VERSION ""

NS_ :

BS_:

BU_: EPS ESP_ECU BCM VCU MPC_CAM ADAS_ECU MCU BSD

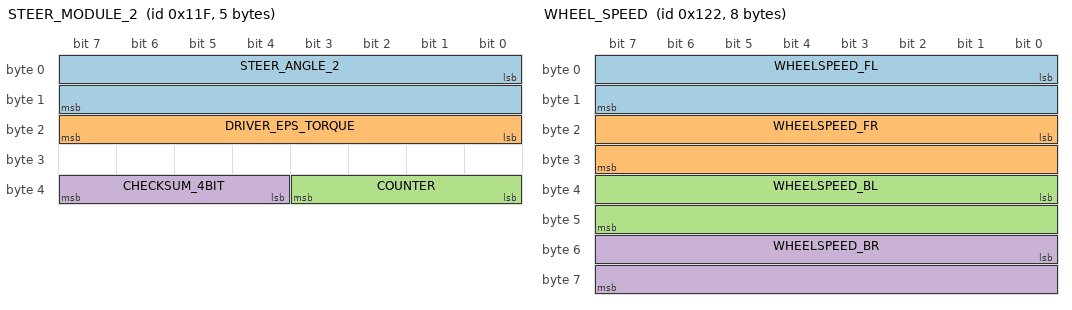
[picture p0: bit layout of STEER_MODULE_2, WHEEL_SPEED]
BO_ 287 STEER_MODULE_2: 5 EPS
 SG_ STEER_ANGLE_2 : 0|16@1- (0.1,0) [-780|780] "deg" MCU,ADAS_ECU
 SG_ DRIVER_EPS_TORQUE : 16|8@1+ (1,0) [0|255] "" MCU,ADAS_ECU
 SG_ COUNTER : 35|4@0+ (1,0) [0|15] "" MCU
 SG_ CHECKSUM_4BIT : 39|4@0+ (1,0) [0|15] "" MCU

BO_ 290 WHEEL_SPEED: 8 ESP_ECU
 SG_ WHEELSPEED_FL : 0|16@1+ (0.1,0) [0|6553.5] "kph" MCU,ADAS_ECU
 SG_ WHEELSPEED_FR : 16|16@1+ (0.1,0) [0|6553.5] "kph" MCU,ADAS_ECU
 SG_ WHEELSPEED_BL : 32|16@1+ (0.1,0) [0|6553.5] "kph" MCU,ADAS_ECU
 SG_ WHEELSPEED_BR : 48|16@1+ (0.1,0) [0|6553.5] "kph" MCU,ADAS_ECU

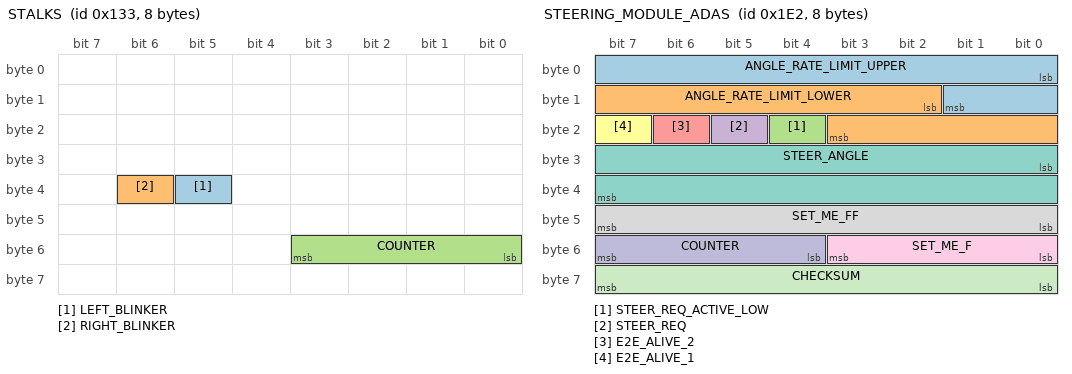
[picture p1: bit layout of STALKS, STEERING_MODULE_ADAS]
BO_ 307 STALKS: 8 BCM
 SG_ LEFT_BLINKER : 37|1@0+ (1,0) [0|1] "" MCU
 SG_ RIGHT_BLINKER : 38|1@0+ (1,0) [0|1] "" MCU
 SG_ COUNTER : 48|4@1+ (1,0) [0|15] "" MCU

BO_ 482 STEERING_MODULE_ADAS: 8 ADAS_ECU
 SG_ ANGLE_RATE_LIMIT_UPPER : 0|10@1- (1,0) [-512|511] "" EPS
 SG_ ANGLE_RATE_LIMIT_LOWER : 10|10@1- (1,0) [-512|511] "" EPS
 SG_ STEER_REQ_ACTIVE_LOW : 20|1@0+ (1,0) [0|1] "" EPS
 SG_ STEER_REQ : 21|1@0+ (1,0) [0|1] "" EPS
 SG_ E2E_ALIVE_2 : 22|1@0+ (1,0) [0|1] "" EPS
 SG_ E2E_ALIVE_1 : 23|1@0+ (1,0) [0|1] "" EPS
 SG_ STEER_ANGLE : 24|16@1- (0.1,0) [-3276.8|3276.7] "deg" EPS
 SG_ SET_ME_FF : 47|8@0+ (1,0) [0|255] "" EPS
 SG_ SET_ME_F : 48|4@1+ (1,0) [0|15] "" EPS
 SG_ COUNTER : 55|4@0+ (1,0) [0|15] "" EPS
 SG_ CHECKSUM : 56|8@1+ (1,0) [0|255] "" EPS

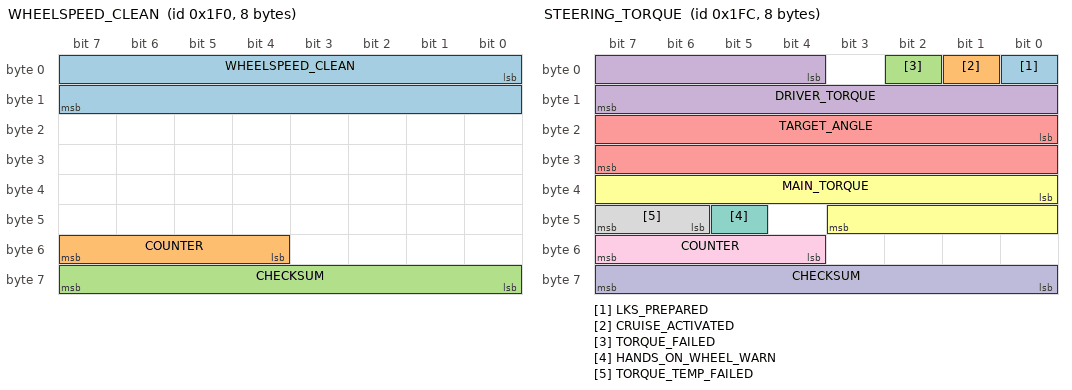
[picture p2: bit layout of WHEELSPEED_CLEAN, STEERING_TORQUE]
BO_ 496 WHEELSPEED_CLEAN: 8 ESP_ECU
 SG_ WHEELSPEED_CLEAN : 0|16@1+ (0.0713,0) [0|4672.6] "kph" MCU
 SG_ COUNTER : 55|4@0+ (1,0) [0|15] "" MCU
 SG_ CHECKSUM : 56|8@1+ (1,0) [0|255] "" MCU

BO_ 508 STEERING_TORQUE: 8 EPS
 SG_ LKS_PREPARED : 0|1@1+ (1,0) [0|1] "" MCU,ADAS_ECU
 SG_ CRUISE_ACTIVATED : 1|1@1+ (1,0) [0|1] "" MCU,ADAS_ECU
 SG_ TORQUE_FAILED : 2|1@1+ (1,0) [0|1] "" MCU,ADAS_ECU
 SG_ DRIVER_TORQUE : 4|12@1- (0.1,0) [-204.8|204.7] "Nm" MCU,ADAS_ECU
 SG_ TARGET_ANGLE : 16|16@1- (0.1,0) [-3276.8|3276.7] "deg" MCU,ADAS_ECU
 SG_ MAIN_TORQUE : 32|12@1- (1,0) [-2048|2047] "" MCU,ADAS_ECU
 SG_ HANDS_ON_WHEEL_WARN : 45|1@1+ (1,0) [0|1] "" MCU,ADAS_ECU
 SG_ TORQUE_TEMP_FAILED : 46|2@1+ (1,0) [0|3] "" MCU,ADAS_ECU
 SG_ COUNTER : 52|4@1+ (1,0) [0|15] "" MCU
 SG_ CHECKSUM : 56|8@1+ (1,0) [0|255] "" MCU

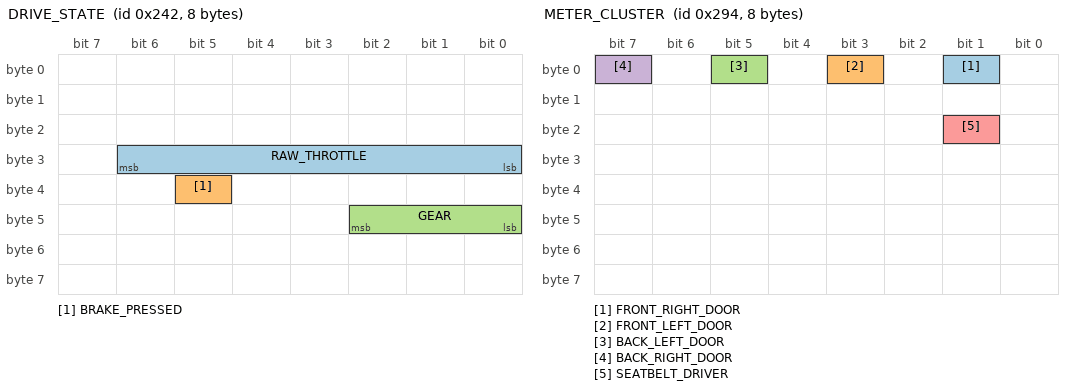
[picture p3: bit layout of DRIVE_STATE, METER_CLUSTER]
BO_ 578 DRIVE_STATE: 8 VCU
 SG_ RAW_THROTTLE : 30|7@0+ (1,0) [0|127] "" MCU
 SG_ BRAKE_PRESSED : 37|1@0+ (1,0) [0|1] "" MCU,ADAS_ECU
 SG_ GEAR : 40|3@1+ (1,0) [0|7] "" MCU

BO_ 660 METER_CLUSTER: 8 BCM
 SG_ FRONT_RIGHT_DOOR : 1|1@1+ (1,0) [0|1] "" MCU
 SG_ FRONT_LEFT_DOOR : 3|1@0+ (1,0) [0|1] "" MCU
 SG_ BACK_LEFT_DOOR : 5|1@1+ (1,0) [0|1] "" MCU
 SG_ BACK_RIGHT_DOOR : 7|1@0+ (1,0) [0|1] "" MCU
 SG_ SEATBELT_DRIVER : 17|1@0+ (1,0) [0|1] "" MCU

BO_ 790 LKAS_HUD_ADAS: 8 MPC_CAM
 SG_ AUTO_LIGHT : 1|2@0+ (1,0) [0|3] "" XXX
 SG_ PT1 : 2|2@1+ (1,0) [0|3] "" MCU
 SG_ LEFT_LANE_STATE : 4|2@1+ (1,0) [0|3] "" MCU
 SG_ LKS_MODE : 6|2@1+ (1,0) [0|3] "" MCU
 SG_ PT2 : 8|2@1+ (1,0) [0|3] "" MCU
 SG_ HANDS_ON_WHEEL_REQ : 10|1@1+ (1,0) [0|1] "" MCU
 SG_ TJA_ICA_STATE : 11|4@1+ (1,0) [0|15] "" MCU
 SG_ HMA_ON_OFF : 15|1@0+ (1,0) [0|1] "" MCU
 SG_ LKAS_OUTPUT : 16|11@1- (1,0) [-1024|1023] "" MCU
 SG_ LKAS_REQ_PREPARE : 27|1@1+ (1,0) [0|1] "" MCU
 SG_ LKAS_ACTIVE : 28|1@1+ (1,0) [0|1] "" MCU
 SG_ SLA_STATE : 29|3@1+ (1,0) [0|7] "" MCU
 SG_ PT3 : 32|2@1+ (1,0) [0|3] "" MCU
 SG_ RIGHT_LANE_STATE : 34|2@1+ (1,0) [0|3] "" MCU
 SG_ LKAS_STATE : 36|4@1+ (1,0) [0|15] "" MCU
 SG_ SPEED_LIMIT_VALUE : 40|8@1+ (5,-5) [-5|1270] "kph" MCU
 SG_ LDSW_TYPE : 49|2@0+ (1,0) [0|3] "" MCU
 SG_ PT4 : 50|2@1+ (1,0) [0|3] "" MCU
 SG_ COUNTER : 52|4@1+ (1,0) [0|15] "" MCU
 SG_ CHECKSUM : 56|8@1+ (1,0) [0|255] "" MCU

BO_ 813 ACC_HUD_ADAS: 8 ADAS_ECU
 SG_ SET_SPEED : 0|8@1+ (0.5,0) [0|127.5] "kph" MCU
 SG_ SET_DISTANCE : 12|3@0+ (1,0) [0|7] "" MCU
 SG_ ACC_STATE : 19|3@1+ (1,0) [0|7] "" MCU
 SG_ ACC_ON2 : 20|1@0+ (1,0) [0|1] "" MCU
 SG_ ACC_ON1 : 22|1@0+ (1,0) [0|1] "" MCU
 SG_ SET_ME_XFF : 47|8@0+ (1,0) [0|255] "" MCU
 SG_ COUNTER : 48|4@1+ (1,0) [0|15] "" MCU
 SG_ SET_ME_XF : 55|4@0+ (1,0) [0|15] "" MCU
 SG_ CHECKSUM : 56|8@1+ (1,0) [0|255] "" MCU

BO_ 814 ACC_CMD: 8 ADAS_ECU
 SG_ ACCEL_CMD : 0|8@1+ (0.05,-5) [-5|7.75] "m/s^2" MCU
 SG_ ACC_ON_1 : 9|1@0+ (1,0) [0|1] "" MCU
 SG_ SET_ME_25_1 : 10|6@1+ (1,0) [0|63] "" MCU
 SG_ ACC_ON_2 : 17|1@0+ (1,0) [0|1] "" MCU
 SG_ SET_ME_25_2 : 18|6@1+ (1,0) [0|63] "" MCU
 SG_ DECEL_FACTOR : 24|4@1+ (1,0) [0|15] "" MCU
 SG_ SET_ME_X8 : 31|4@0+ (1,0) [0|15] "" MCU
 SG_ ACCEL_FACTOR : 32|4@1+ (1,0) [0|15] "" MCU
 SG_ CMD_REQ_ACTIVE_LOW : 36|1@0+ (1,0) [0|1] "" MCU
 SG_ SET_ME_1 : 38|1@0+ (1,0) [0|1] "" MCU
 SG_ STANDSTILL_RESUME : 39|1@0+ (1,0) [0|1] "" MCU
 SG_ STANDSTILL_STATE : 40|1@0+ (1,0) [0|1] "" MCU
 SG_ ACC_REQ_NOT_STANDSTILL : 43|1@0+ (1,0) [0|1] "" MCU
 SG_ ACC_CONTROLLABLE_AND_ON : 44|1@0+ (1,0) [0|1] "" MCU
 SG_ ACC_OVERRIDE_OR_STANDSTILL : 45|1@0+ (1,0) [0|1] "" MCU
 SG_ COUNTER : 48|4@1+ (1,0) [0|15] "" MCU
 SG_ SET_ME_XF : 55|4@0+ (1,0) [0|15] "" MCU
 SG_ CHECKSUM : 56|8@1+ (1,0) [0|255] "" MCU

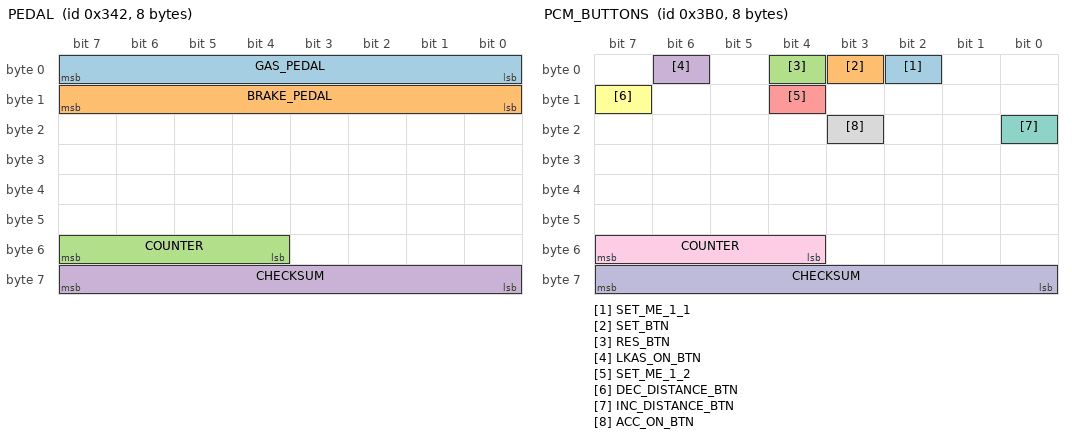
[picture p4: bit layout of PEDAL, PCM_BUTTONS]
BO_ 834 PEDAL: 8 VCU
 SG_ GAS_PEDAL : 0|8@1+ (0.01,0) [0|2.55] "" MCU
 SG_ BRAKE_PEDAL : 8|8@1+ (0.01,0) [0|2.55] "" MCU
 SG_ COUNTER : 55|4@0+ (1,0) [0|15] "" MCU
 SG_ CHECKSUM : 56|8@1+ (1,0) [0|255] "" MCU

BO_ 944 PCM_BUTTONS: 8 MCU
 SG_ SET_ME_1_1 : 2|1@0+ (1,0) [0|1] "" MCU
 SG_ SET_BTN : 3|1@0+ (1,0) [0|1] "" MCU
 SG_ RES_BTN : 4|1@0+ (1,0) [0|1] "" MCU
 SG_ LKAS_ON_BTN : 6|1@0+ (1,0) [0|1] "" MCU
 SG_ SET_ME_1_2 : 12|1@0+ (1,0) [0|1] "" MCU
 SG_ DEC_DISTANCE_BTN : 15|1@0+ (1,0) [0|1] "" MCU
 SG_ INC_DISTANCE_BTN : 16|1@0+ (1,0) [0|1] "" MCU
 SG_ ACC_ON_BTN : 19|1@0+ (1,0) [0|1] "" MCU
 SG_ COUNTER : 55|4@0+ (1,0) [0|15] "" MCU
 SG_ CHECKSUM : 63|8@0+ (1,0) [0|255] "" MCU

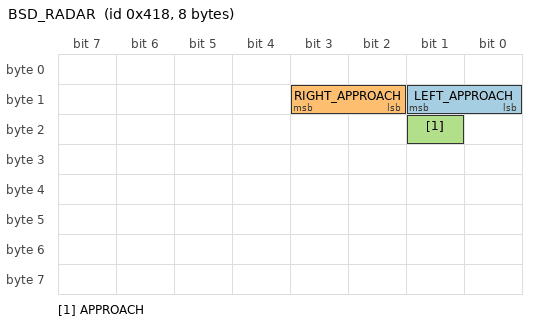
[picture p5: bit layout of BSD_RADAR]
BO_ 1048 BSD_RADAR: 8 BSD
 SG_ LEFT_APPROACH : 9|2@0+ (1,0) [0|3] "" MCU,ADAS_ECU
 SG_ RIGHT_APPROACH : 11|2@0+ (1,0) [0|3] "" MCU,ADAS_ECU
 SG_ APPROACH : 17|1@0+ (1,0) [0|1] "" MCU,ADAS_ECU

CM_ BO_ 287 "EPS steering wheel angle + driver torque. Validated: angle range plausible, DRIVER_EPS_TORQUE stays near 0 when hands-off.";
CM_ BO_ 290 "Per-wheel speed from ESP (FL/FR/BL/BR). Scale 0.1 kph/bit. Use WHEELSPEED_CLEAN (0x1F0) for the aggregated filtered value openpilot consumes.";
CM_ BO_ 307 "Turn signal / stalk info. Validated: LEFT_BLINKER and RIGHT_BLINKER transition 0->1 during lane change events.";
CM_ BO_ 482 "Lateral steering command sent by MPC camera/ADAS ECU to EPS. Blocked by panda on bus 2; panda injects its own on bus 0.";
CM_ BO_ 496 "Wheel speed (cleaned average). Validated: 0-127 km/h matching driving speed.";
CM_ BO_ 508 "Column steering torque from EPS.";
CM_ BO_ 578 "Drivetrain state: gear, brake pressed, raw throttle.";
CM_ BO_ 660 "Body/meter cluster: doors + seatbelt.";
CM_ BO_ 790 "LKAS HUD ADAS message from camera. Blocked by panda on bus 2; panda re-injects. PT1-PT4 name previously-unnamed bits so a decode/repack round-trips byte-exact: the modules validate this frame's full bit pattern and fail-safe (latched DTCs) if a regenerated frame flips any bit. On-car PT3 bit 32 is constant 1; an unnamed bit packs as 0.";
CM_ BO_ 813 "ACC HUD ADAS message (cruise set speed, distance, ACC state).";
CM_ BO_ 814 "ACC acceleration command from ADAS ECU. Blocked by panda on bus 2 when OP longitudinal active.";
CM_ BO_ 834 "Gas/brake pedal percentages.";
CM_ BO_ 944 "Steering-wheel cruise control buttons.";
VAL_ 508 TORQUE_TEMP_FAILED 1 "TooLarge" 2 "TooFast" 3 "Both";
VAL_ 578 GEAR 4 "D" 2 "R" 3 "N" 1 "P";
VAL_ 790 AUTO_LIGHT 1 "OFF" 2 "ON";
VAL_ 790 LEFT_LANE_STATE 0 "OFF" 1 "GREEN" 2 "ORANGE";
VAL_ 790 LKS_MODE 0 "OFF" 1 "DIVERGE" 2 "KEEPING" 3 "ALL";
VAL_ 790 TJA_ICA_STATE 0 "OFF" 1 "PASSIVE" 2 "ACTIVE1" 3 "ACTIVE2" 4 "FAULT";
VAL_ 790 SLA_STATE 0 "OFF" 1 "FUSION_MODE" 2 "VISION_MODE" 3 "NV_ONLY_MODE" 4 "DEFECT";
VAL_ 790 RIGHT_LANE_STATE 0 "OFF" 1 "GREEN" 2 "ORANGE";
VAL_ 790 LKAS_STATE 2 "ACTIVE" 1 "OFF";
VAL_ 790 LDSW_TYPE 0 "VIBRATE" 1 "SOUND" 2 "ALL";
VAL_ 813 SET_DISTANCE 4 "4bar" 3 "3bar" 2 "2bar" 1 "1bar";
VAL_ 813 ACC_STATE 0 "OFF" 2 "ACC_ON" 3 "ACC_ACTIVE" 5 "FORCE_ACCEL" 7 "ERROR";
